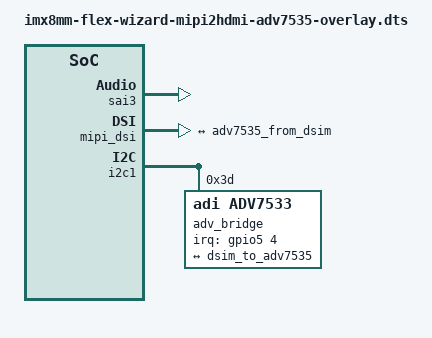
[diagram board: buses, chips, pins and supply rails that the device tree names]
// SPDX-License-Identifier: (GPL-2.0+ OR MIT)
/*
 * Copyright 2020 TechNexion Ltd.
 *
 * Author: Richard Hu <richard.hu@technexion.com>
 *         Ray Chang <ray.chang@technexion.com>
 *
 */

/dts-v1/;
/plugin/;

#include <dt-bindings/interrupt-controller/irq.h>
#include <dt-bindings/gpio/gpio.h>
#include <dt-bindings/clock/imx8mm-clock.h>

/ {
	fragment@0 {
		target-path = "/";
		__overlay__ {
			sound-adv7535 {
				compatible = "simple-audio-card";
				simple-audio-card,name = "adv7535-hdmi";
				simple-audio-card,mclk-fs = <256>;
				simple-audio-card,mclk-clk-id = <1>;
				simple-audio-card,format = "i2s";
				simple-audio-card,bitclock-master = <&sound_master>;
				simple-audio-card,frame-master = <&sound_master>;

				sound_master: simple-audio-card,cpu {
					sound-dai = <&sai3>;
				};

				simple-audio-card,codec {
					sound-dai = <&adv_bridge>;
				};
			};
		};
	};

	fragment@1 {
		target = <&sai3>;
		__overlay__ {
			clocks = <&clk IMX8MM_CLK_SAI3_IPG>, <&clk IMX8MM_CLK_DUMMY>,
				<&clk IMX8MM_CLK_SAI3_ROOT>, <&clk IMX8MM_CLK_DUMMY>,
				<&clk IMX8MM_CLK_DUMMY>, <&clk IMX8MM_AUDIO_PLL1_OUT>,
				<&clk IMX8MM_AUDIO_PLL2_OUT>;
			clock-names = "bus", "mclk0", "mclk1", "mclk2", "mclk3", "pll8k", "pll11k";

			#sound-dai-cells = <0>;
			status = "okay";
		};
	};

	fragment@2 {
		target = <&mipi_dsi>;
		__overlay__ {
			status = "okay";

			port@1 {
				dsim_to_adv7535: endpoint {
					remote-endpoint = <&adv7535_from_dsim>;
					attach-bridge;
				};
			};
		};
	};

	fragment@3 {
		target = <&i2c1>;
		__overlay__ {
			#address-cells = <1>;
			#size-cells = <0>;
			status = "okay";

			adv_bridge: adv7535@3d {
				compatible = "adi,adv7533";
				reg = <0x3d>;
				adi,addr-cec = <0x3b>;
				adi,dsi-lanes = <4>;
				pinctrl-names = "default";
				pinctrl-0 = <&pinctrl_touch_irq>;
				interrupt-parent = <&gpio5>;
				interrupts = <4 IRQ_TYPE_LEVEL_LOW>;
				status = "okay";
				#sound-dai-cells = <0>;

				port {
					adv7535_from_dsim: endpoint {
						remote-endpoint = <&dsim_to_adv7535>;
					};
				};
			};
		};
	};
};
